# ESP32S31_RADIO register map
Vendor: Espressif; Series: ESP32-S31; File version: 3.52
Registers are 32-bit, read-write, no defined reset value unless marked. A register's access mark holds for its fields unless they carry their own. Offsets are from the block's base; [hi:lo] are bit positions; 'fields as' and 'values as' point back to an identical list.

## PHY_BASEBAND_CONFIG_ORACLE — PHY/baseband configuration registers recovered from complete rev0 ROM bodies and complete pinned libphy leaves. Operation-derived fields keep UNKNOWN where neither public documentation nor an independent symbol establishes the electrical meaning.
Base 0x20100000
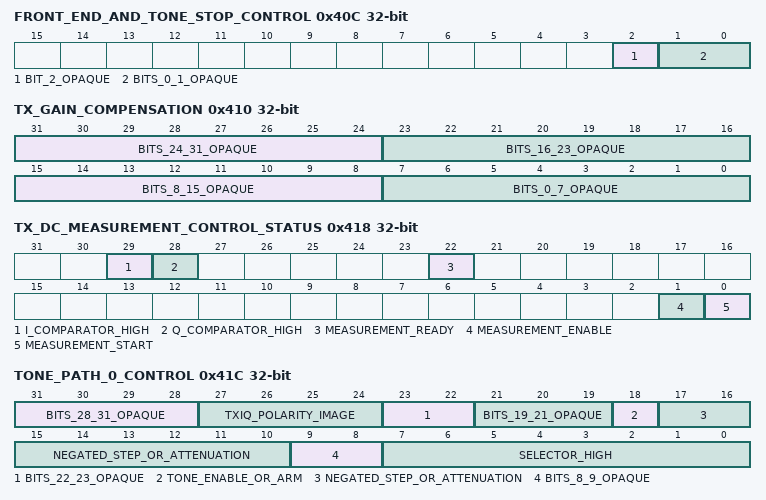
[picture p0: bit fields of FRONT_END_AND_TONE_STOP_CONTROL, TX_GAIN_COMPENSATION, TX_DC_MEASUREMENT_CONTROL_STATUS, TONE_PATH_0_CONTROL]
0x40C FRONT_END_AND_TONE_STOP_CONTROL — Project-assigned name. Shared word whose bit 2 is set by complete phy_fe_reg_init. Complete phy_start_tx_tone_step clears bits 1:0 and complete phy_stop_tx_tone sets them.
  [2] BIT_2_OPAQUE — Opaque: meaning not established.
  [1:0] BITS_0_1_OPAQUE — Opaque: meaning not established. Two-bit field cleared before the ROM power-control tone and set by its complete cleanup; the individual bit meanings are unknown.
0x410 TX_GAIN_COMPENSATION — Project-assigned name. Complete phy_txgain_comp_pacfg_new(1) publishes four ordered byte updates.
  [31:24] BITS_24_31_OPAQUE — Opaque: meaning not established.
  [23:16] BITS_16_23_OPAQUE — Opaque: meaning not established.
  [15:8] BITS_8_15_OPAQUE — Opaque: meaning not established.
  [7:0] BITS_0_7_OPAQUE — Opaque: meaning not established.
0x414 TX_GAIN_COMPENSATION_AUX wo — Project-assigned name. Pinned libphy.a[phy_reg.o] phy_start_tx_tone_step_new writes the full zero image while disabling TX-gain compensation.
  [31:0] BITS_0_31_OPAQUE — Opaque: meaning not established.
0x418 TX_DC_MEASUREMENT_CONTROL_STATUS — Project-assigned name. Complete phy_txdc_cal triggers measurement with bits 1 and 0, polls ready bit 22, samples I and Q comparator bits 29 and 28 through independent reads, then clears bits 1 and 0.
  [29] I_COMPARATOR_HIGH ro — Project-assigned name.
  [28] Q_COMPARATOR_HIGH ro — Project-assigned name.
  [22] MEASUREMENT_READY ro — Project-assigned name.
  [1] MEASUREMENT_ENABLE — Project-assigned name.
  [0] MEASUREMENT_START — Project-assigned name.
0x41C TONE_PATH_0_CONTROL — Project-assigned name. First calibration-tone path word. Complete source bodies prove the packed selector, negated step or attenuation, enable/arm bit and TX-IQ mismatch images; the high nibble is preserved and remains electrically unknown.
  [31:28] BITS_28_31_OPAQUE — Opaque: meaning not established. High nibble preserved by all recovered tone updates and retained by the TX-IQ save/restore transaction.
  [27:24] TXIQ_POLARITY_IMAGE — Project-assigned name. Four-bit mismatch polarity image: first configuration writes bit 26, while the second phase writes nibble 1 or 8.
  [23:22] BITS_22_23_OPAQUE — Opaque: meaning not established. Complete general and first-polarity tone writers clear these bits.
  [21:19] BITS_19_21_OPAQUE — Opaque: meaning not established. Three-bit image set to binary 101 for the first mismatch-power polarity and otherwise cleared by general tone setup.
  [18] TONE_ENABLE_OR_ARM — Project-assigned name. Set by tone start and by each PWDET sample-arm edge; cleared by stop and sample cleanup.
  [17:10] NEGATED_STEP_OR_ATTENUATION — Project-assigned name. Two's-complement negated eight-bit tone step or attenuation.
  [9:8] BITS_8_9_OPAQUE — Opaque: meaning not established. Complete tone writers clear these bits; their hardware meaning is unknown.
  [7:0] SELECTOR_HIGH — Project-assigned name. Upper eight bits of the evidenced ten-bit selector; bits 1:0 are in TONE_SELECTOR_CONTROL.
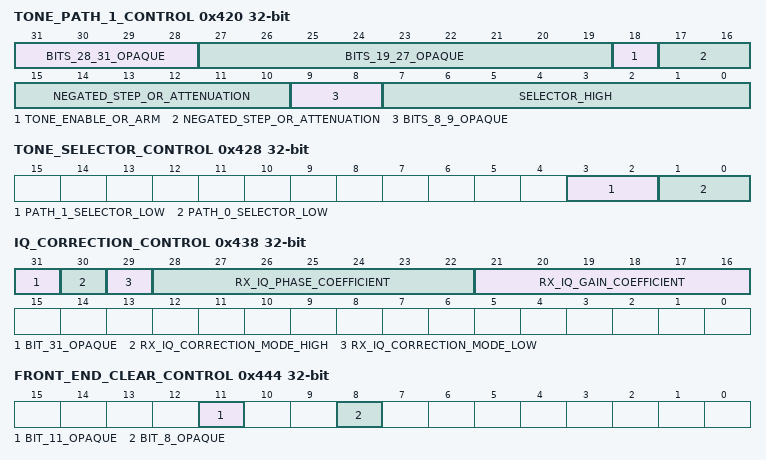
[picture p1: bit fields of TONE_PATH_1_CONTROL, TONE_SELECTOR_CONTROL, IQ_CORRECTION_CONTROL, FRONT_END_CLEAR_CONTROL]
0x420 TONE_PATH_1_CONTROL — Project-assigned name. Second calibration-tone path word. All currently evidenced calls publish a disabled zero low image while preserving the high nibble.
  [31:28] BITS_28_31_OPAQUE — Opaque: meaning not established. High nibble preserved by all recovered second-path tone updates.
  [27:19] BITS_19_27_OPAQUE — Opaque: meaning not established.
    0=CLEARED
  [18] TONE_ENABLE_OR_ARM — Project-assigned name.
  [17:10] NEGATED_STEP_OR_ATTENUATION — Project-assigned name.
    0=CLEARED
  [9:8] BITS_8_9_OPAQUE — Opaque: meaning not established.
    0=CLEARED
  [7:0] SELECTOR_HIGH — Project-assigned name.
    0=CLEARED
0x424 RX_GAIN_DC_CONTROL — Project-assigned name. Complete rev0 ROM phy_set_rx_gain_cal_dc at 0x2f829858, size 0x206, sets bits 6:5 before the bounded RX-gain DC calibration graph and clears the same pair during the common cleanup tail. Their narrower electrical meaning is not independently proved.
  [6:5] BITS_5_6_OPAQUE — Opaque: meaning not established.
    0=DISABLED (Common phy_set_rx_gain_cal_dc cleanup value.); 3=ENABLED (phy_set_rx_gain_cal_dc calibration-prefix value.)
0x428 TONE_SELECTOR_CONTROL — Project-assigned name. Low two selector bits for each calibration-tone path, updated through separate fresh-read edges.
  [3:2] PATH_1_SELECTOR_LOW — Project-assigned name.
  [1:0] PATH_0_SELECTOR_LOW — Project-assigned name.
0x438 IQ_CORRECTION_CONTROL — Project-assigned name. Shared RX-IQ coefficient and correction-mode word.
  [31] BIT_31_OPAQUE — Opaque: meaning not established. Complete phy_fe_reg_init sets bit 31 after the repeated ADC-control writes.
  [30] RX_IQ_CORRECTION_MODE_HIGH — Project-assigned name. High bit of the correction-mode field updated through a distinct fresh-read edge by the RXIQ parent.
  [29] RX_IQ_CORRECTION_MODE_LOW — Project-assigned name. Low bit of the correction-mode field updated through a distinct fresh-read edge by the RXIQ parent.
  [28:22] RX_IQ_PHASE_COEFFICIENT — Project-assigned name.
  [21:16] RX_IQ_GAIN_COEFFICIENT — Project-assigned name.
0x444 FRONT_END_CLEAR_CONTROL — Project-assigned name. Complete phy_fe_reg_init clears bits 8 and 11 in two separately ordered RMW edges.
  [11] BIT_11_OPAQUE — Opaque: meaning not established.
  [8] BIT_8_OPAQUE — Opaque: meaning not established.
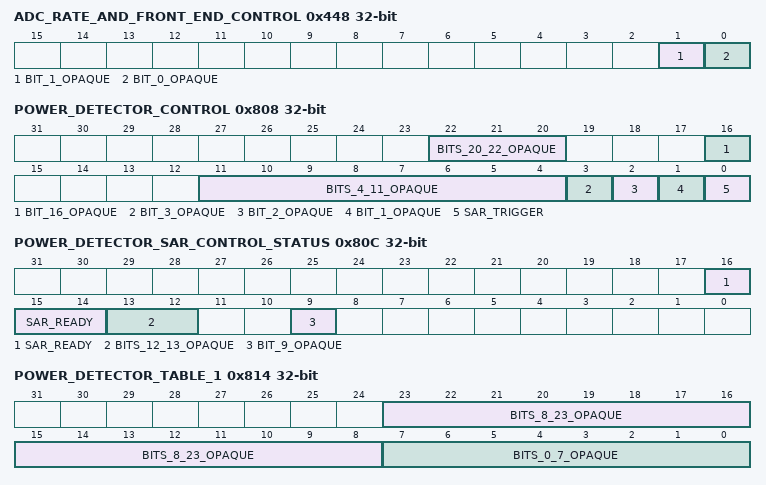
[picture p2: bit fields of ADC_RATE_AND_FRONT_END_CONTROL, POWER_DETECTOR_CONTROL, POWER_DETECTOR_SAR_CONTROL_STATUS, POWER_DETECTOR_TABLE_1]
0x448 ADC_RATE_AND_FRONT_END_CONTROL — Project-assigned name. Complete phy_adc_rate_set and phy_dac_rate_set publish rate bit zero into bits 1 and 0 through separate RMW edges. Front-end initialization and update set the same bits in their independently evidenced order.
  [1] BIT_1_OPAQUE — Opaque: meaning not established.
  [0] BIT_0_OPAQUE — Opaque: meaning not established.
0x808 POWER_DETECTOR_CONTROL — Project-assigned name. Shared PWDET trigger, calibration and background-control word.
  [22:20] BITS_20_22_OPAQUE — Opaque: meaning not established.
  [16] BIT_16_OPAQUE — Opaque: meaning not established.
  [11:4] BITS_4_11_OPAQUE — Opaque: meaning not established.
  [3] BIT_3_OPAQUE — Opaque: meaning not established.
  [2] BIT_2_OPAQUE — Opaque: meaning not established.
  [1] BIT_1_OPAQUE — Opaque: meaning not established.
  [0] SAR_TRIGGER — Project-assigned name.
0x80C POWER_DETECTOR_SAR_CONTROL_STATUS — Project-assigned name. PWDET SAR configuration and three-bit ready status.
  [16:14] SAR_READY ro — Project-assigned name. Hardware completion state sampled by the complete power-detector paths; neither source writes these bits.
  [13:12] BITS_12_13_OPAQUE — Opaque: meaning not established.
  [9] BIT_9_OPAQUE — Opaque: meaning not established.
0x810 WORD_0810_OPAQUE wo — Opaque: meaning not established. Complete phy_pwdet_reg_init writes 0x0f0f0fff.
0x814 POWER_DETECTOR_TABLE_1 — Project-assigned name. Complete initialization writes 0x00ff0f64; TX-DC calibration temporarily replaces the low byte.
  [23:8] BITS_8_23_OPAQUE — Opaque: meaning not established.
  [7:0] BITS_0_7_OPAQUE — Opaque: meaning not established.
0x818 POWER_DETECTOR_REFERENCE wo — Project-assigned name. PWDET reference word; initialization writes 0xaaaa and later paths publish 0, 0x5555 or 0xaaaa.
  [15:0] REFERENCE_CODE — Project-assigned name.
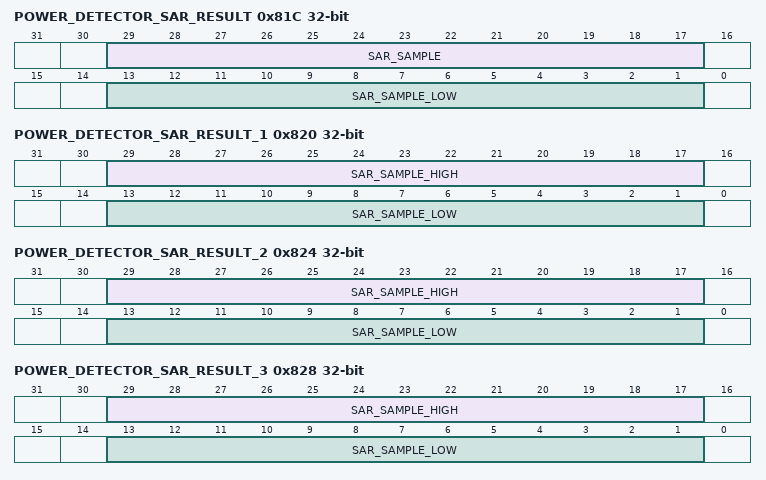
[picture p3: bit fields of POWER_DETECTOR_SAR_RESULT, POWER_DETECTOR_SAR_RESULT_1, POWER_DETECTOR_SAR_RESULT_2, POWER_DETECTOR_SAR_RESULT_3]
0x81C POWER_DETECTOR_SAR_RESULT ro — Project-assigned name. First of four consecutive SAR result words. phy_get_tone_sar_dout_ consumes its upper thirteen-bit sample; phy_get_fm_sar_dout consumes both thirteen-bit halves from all four words.
  [29:17] SAR_SAMPLE — Project-assigned name.
  [13:1] SAR_SAMPLE_LOW — Project-assigned name.
0x820 POWER_DETECTOR_SAR_RESULT_1 ro — Project-assigned name. Second of four consecutive dual thirteen-bit SAR result words consumed by complete phy_get_fm_sar_dout.
  [29:17] SAR_SAMPLE_HIGH — Project-assigned name.
  [13:1] SAR_SAMPLE_LOW — Project-assigned name.
0x824 POWER_DETECTOR_SAR_RESULT_2 ro — Project-assigned name. Third of four consecutive dual thirteen-bit SAR result words consumed by complete phy_get_fm_sar_dout.
  fields as POWER_DETECTOR_SAR_RESULT_1
0x828 POWER_DETECTOR_SAR_RESULT_3 ro — Project-assigned name. Fourth of four consecutive dual thirteen-bit SAR result words consumed by complete phy_get_fm_sar_dout.
  fields as POWER_DETECTOR_SAR_RESULT_1
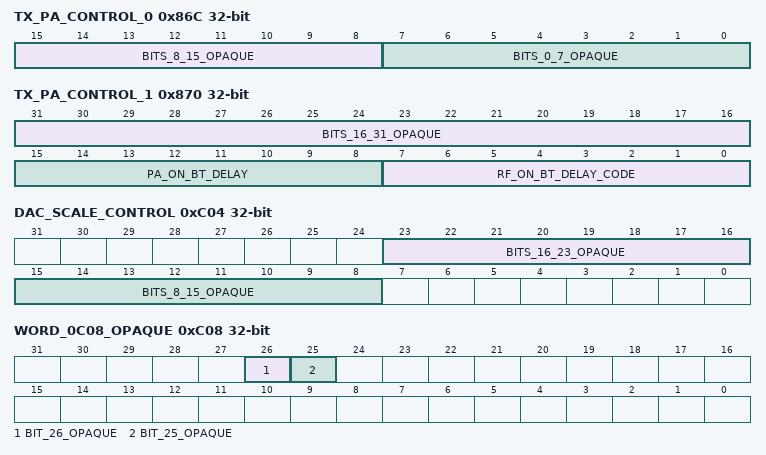
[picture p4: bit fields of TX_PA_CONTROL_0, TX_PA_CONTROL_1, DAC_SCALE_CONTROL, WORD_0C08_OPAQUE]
0x86C TX_PA_CONTROL_0 — Project-assigned name. Shared front-end low byte and PA-on high byte.
  [15:8] BITS_8_15_OPAQUE — Opaque: meaning not established.
  [7:0] BITS_0_7_OPAQUE — Opaque: meaning not established.
0x870 TX_PA_CONTROL_1 — Project-assigned name. Complete phy_tx_paon_set publishes 0x0a0e in the high half and 0xc8 in byte one. Complete ble_tx_config_check independently names the low two bytes as Bluetooth RF/PA turn-on delays.
  [31:16] BITS_16_31_OPAQUE — Opaque: meaning not established.
  [15:8] PA_ON_BT_DELAY — Project-assigned name. Bluetooth PA-on delay.
  [7:0] RF_ON_BT_DELAY_CODE — Project-assigned name. Eight-bit RF-on delay code printed by the vendor checker after integer division by 80. The electrical time unit of the raw code is not otherwise assumed.
0xC04 DAC_SCALE_CONTROL — Project-assigned name. Complete ROM tone start clears both byte-wide DAC-scale fields before measurement; complete phy_stop_tx_tone(1) restores both fields to 0xff through separate fresh-read writes.
  [23:16] BITS_16_23_OPAQUE — Opaque: meaning not established.
  [15:8] BITS_8_15_OPAQUE — Opaque: meaning not established.
0xC08 WORD_0C08_OPAQUE — Opaque: meaning not established. Both complete source bodies set bit 25 and then bit 26 through separate fresh-read RMW edges.
  [26] BIT_26_OPAQUE — Opaque: meaning not established.
  [25] BIT_25_OPAQUE — Opaque: meaning not established.
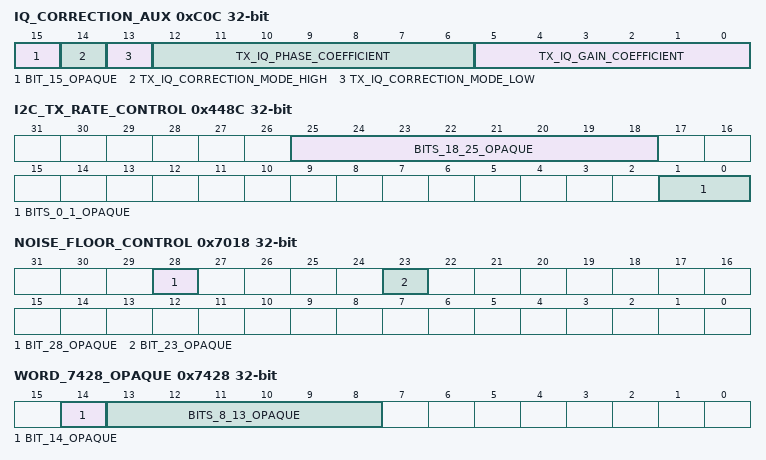
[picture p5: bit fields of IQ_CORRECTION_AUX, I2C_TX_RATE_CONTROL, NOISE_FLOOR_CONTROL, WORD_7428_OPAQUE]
0xC0C IQ_CORRECTION_AUX — Project-assigned name. Shared TX-IQ coefficient and correction-mode word.
  [15] BIT_15_OPAQUE — Opaque: meaning not established. Complete phy_fe_reg_init sets bit 15 after the shared correction-mode initialization.
  [14] TX_IQ_CORRECTION_MODE_HIGH — Project-assigned name. High bit of the auxiliary correction-mode field updated through a distinct fresh-read edge by the RXIQ parent.
  [13] TX_IQ_CORRECTION_MODE_LOW — Project-assigned name. Low bit of the auxiliary correction-mode field updated through a distinct fresh-read edge by the RXIQ parent.
  [12:6] TX_IQ_PHASE_COEFFICIENT — Project-assigned name.
  [5:0] TX_IQ_GAIN_COEFFICIENT — Project-assigned name.
0xC20 WORD_0C20_OPAQUE — Opaque: meaning not established. Final complete phy_fe_reg_init RMW replaces the low byte with 0x57.
  [7:0] BITS_0_7_OPAQUE — Opaque: meaning not established.
0x448C I2C_TX_RATE_CONTROL — Project-assigned name. Complete phy_i2c_txrate_init replaces both evidenced rate fields before dispatching TX-gain compensation.
  [25:18] BITS_18_25_OPAQUE — Opaque: meaning not established.
  [1:0] BITS_0_1_OPAQUE — Opaque: meaning not established.
0x7018 NOISE_FLOOR_CONTROL — Project-assigned name. Complete phy_noise_floor_auto_set sets both control bits.
  [28] BIT_28_OPAQUE — Opaque: meaning not established.
  [23] BIT_23_OPAQUE — Opaque: meaning not established.
0x7400 WORD_7400_OPAQUE — Opaque: meaning not established. Complete phy_bb_reg_init sets bits 14:13.
  [14:13] BITS_13_14_OPAQUE — Opaque: meaning not established.
0x7428 WORD_7428_OPAQUE — Opaque: meaning not established. Complete phy_bb_reg_init sets bit 14 and replaces bits 13:8 with 0x15.
  [14] BIT_14_OPAQUE — Opaque: meaning not established.
  [13:8] BITS_8_13_OPAQUE — Opaque: meaning not established.
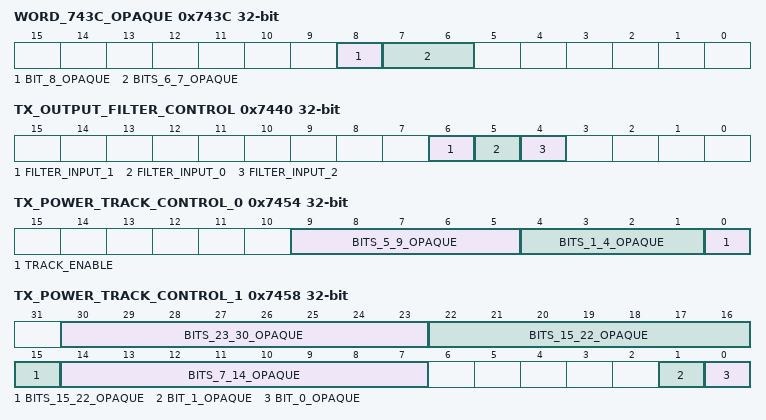
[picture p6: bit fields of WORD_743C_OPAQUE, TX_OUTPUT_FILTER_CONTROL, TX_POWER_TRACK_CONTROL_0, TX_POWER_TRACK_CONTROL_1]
0x743C WORD_743C_OPAQUE — Opaque: meaning not established. Complete phy_bb_reg_init clears bits 8:6 through two fresh-read updates.
  [8] BIT_8_OPAQUE — Opaque: meaning not established.
  [7:6] BITS_6_7_OPAQUE — Opaque: meaning not established.
0x7440 TX_OUTPUT_FILTER_CONTROL — Project-assigned name. Complete phy_bbtx_outfilter replaces bits five, six and four through three independent fresh-read RMWs.
  [6] FILTER_INPUT_1 — Project-assigned name.
  [5] FILTER_INPUT_0 — Project-assigned name.
  [4] FILTER_INPUT_2 — Project-assigned name.
0x7454 TX_POWER_TRACK_CONTROL_0 — Project-assigned name. Complete phy_bb_txpwr_track publishes enable plus two initialization fields.
  [9:5] BITS_5_9_OPAQUE — Opaque: meaning not established.
  [4:1] BITS_1_4_OPAQUE — Opaque: meaning not established.
  [0] TRACK_ENABLE — Project-assigned name.
0x7458 TX_POWER_TRACK_CONTROL_1 — Project-assigned name. Complete phy_bb_txpwr_track clears bits 1:0 and publishes three eight-bit tracking values.
  [30:23] BITS_23_30_OPAQUE — Opaque: meaning not established.
  [22:15] BITS_15_22_OPAQUE — Opaque: meaning not established.
  [14:7] BITS_7_14_OPAQUE — Opaque: meaning not established.
  [1] BIT_1_OPAQUE — Opaque: meaning not established.
  [0] BIT_0_OPAQUE — Opaque: meaning not established.
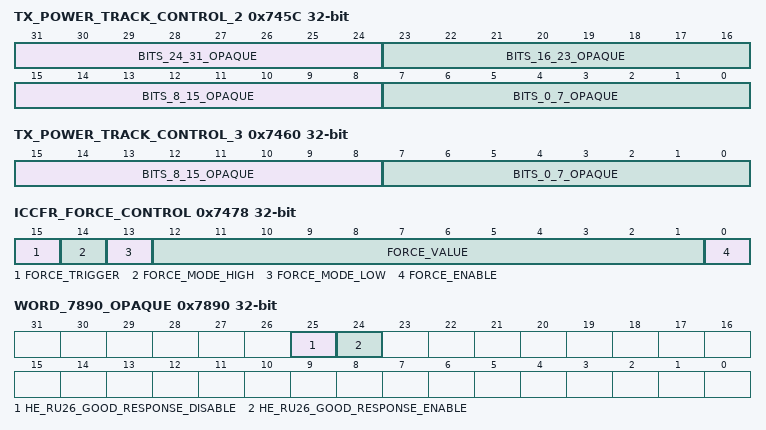
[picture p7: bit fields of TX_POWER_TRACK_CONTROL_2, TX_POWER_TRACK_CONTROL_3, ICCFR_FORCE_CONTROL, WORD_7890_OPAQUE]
0x745C TX_POWER_TRACK_CONTROL_2 — Project-assigned name. Complete phy_bb_txpwr_track publishes four byte-wide tracking values.
  fields as TX_GAIN_COMPENSATION
0x7460 TX_POWER_TRACK_CONTROL_3 — Project-assigned name. Complete phy_bb_txpwr_track publishes two byte-wide tracking values.
  fields as TX_PA_CONTROL_0
0x7468 HCCFR_CONTROL — Project-assigned name. Complete phy_config_hccfr replaces bit 22 with the low bit of its first argument.
  [22] ENABLE — Project-assigned name. Complete phy_config_hccfr writes zero to disable HCCFR and one to enable it.
    0=DISABLED (Disable HCCFR processing.); 1=ENABLED (Enable HCCFR processing.)
0x746C HCCFR_VALUE — Project-assigned name. Complete phy_config_hccfr replaces the low twelve bits with its second argument.
  [11:0] VALUE — Project-assigned name. Complete phy_config_hccfr retains the caller value to this twelve-bit field; every representable field image is accepted by the recovered leaf.
0x7478 ICCFR_FORCE_CONTROL — Project-assigned name. Complete phy_force_iccfr publishes five fields through five separately ordered fresh-read RMWs.
  [15] FORCE_TRIGGER — Project-assigned name.
  [14] FORCE_MODE_HIGH — Project-assigned name.
  [13] FORCE_MODE_LOW — Project-assigned name.
  [12:1] FORCE_VALUE — Project-assigned name. Complete phy_force_iccfr retains the caller value to this twelve-bit field; every representable field image is accepted by the recovered leaf.
  [0] FORCE_ENABLE — Project-assigned name. Complete phy_force_iccfr writes zero to disable the forced ICCFR value and one to enable it.
    0=DISABLED (Use the ordinary ICCFR value path.); 1=ENABLED (Use the forced ICCFR value.)
0x747C ICCFR_ENABLE_CONTROL — Project-assigned name. Complete phy_iccfr_en writes three to bits 26:25 for a zero argument and clears them for a nonzero argument.
  [26:25] GATE — Project-assigned name. Complete phy_iccfr_en writes zero for a nonzero enable input and three for a zero input; the other two encodings are not evidenced.
    0=ENABLED (Enable ICCFR through the recovered zero gate image.); 3=DISABLED (Disable ICCFR through the recovered all-ones gate image.)
0x7808 WORD_7808_OPAQUE — Opaque: meaning not established. Complete phy_bb_reg_init replaces bits 13:7 with 0x60.
  [13:7] BITS_7_13_OPAQUE — Opaque: meaning not established.
0x7890 WORD_7890_OPAQUE — Opaque: meaning not established. Complete phy_bb_reg_init and phy_hemu_ru26_good_res both clear bit 25 then set bit 24 through separate fresh-read RMWs.
  [25] HE_RU26_GOOD_RESPONSE_DISABLE — Project-assigned name.
  [24] HE_RU26_GOOD_RESPONSE_ENABLE — Project-assigned name.
0x78DC WORD_78DC_OPAQUE — Opaque: meaning not established. Complete phy_bb_reg_init replaces bits 13:7 with two.
  [13:7] BITS_7_13_OPAQUE — Opaque: meaning not established.
0x78E4 WORD_78E4_OPAQUE — Opaque: meaning not established. Complete phy_bb_reg_init clears bit 22.
  [22] BIT_22_OPAQUE — Opaque: meaning not established.
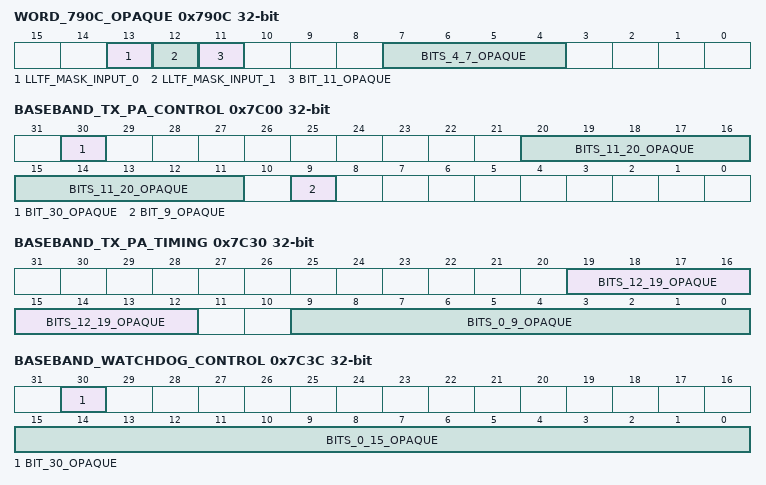
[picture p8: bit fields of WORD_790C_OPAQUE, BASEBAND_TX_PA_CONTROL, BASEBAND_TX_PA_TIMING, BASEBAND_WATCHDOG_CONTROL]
0x790C WORD_790C_OPAQUE — Opaque: meaning not established. Complete phy_bb_reg_init clears bit 11; complete phy_lltf_mask_en independently replaces bits thirteen and twelve; complete phy_chan_dump_cfg replaces bits 7:4 and bit 11 through separate fresh-read RMWs.
  [13] LLTF_MASK_INPUT_0 — Project-assigned name.
  [12] LLTF_MASK_INPUT_1 — Project-assigned name.
  [11] BIT_11_OPAQUE — Opaque: meaning not established.
  [7:4] BITS_4_7_OPAQUE — Opaque: meaning not established. Complete phy_chan_dump_cfg replaces bits 7:4 with the low nibble of its first argument.
0x7980 WORD_7980_OPAQUE — Opaque: meaning not established. Complete phy_bb_reg_init clears bit 25.
  [25] BIT_25_OPAQUE — Opaque: meaning not established.
0x7A28 WORD_7A28_OPAQUE — Opaque: meaning not established. Complete phy_bb_reg_init clears bit 22.
  [22] BIT_22_OPAQUE — Opaque: meaning not established.
0x7C00 BASEBAND_TX_PA_CONTROL — Project-assigned name. Complete phy_bb_reg_init sets bit 9; complete phy_tx_paon_set replaces bits 20:11; complete phy_chan_dump_cfg replaces bit 30 with the low bit of its second argument.
  [30] BIT_30_OPAQUE — Opaque: meaning not established. Complete phy_chan_dump_cfg replaces bit 30 with the low bit of its second argument.
  [20:11] BITS_11_20_OPAQUE — Opaque: meaning not established.
  [9] BIT_9_OPAQUE — Opaque: meaning not established.
0x7C08 BASEBAND_WATCHDOG_STATUS ro — Project-assigned name. Complete phy_bb_wdt_get_status returns one unrestricted full-word read.
  [31:0] STATUS — Project-assigned name. Complete unrestricted watchdog status value returned by phy_bb_wdt_get_status.
0x7C30 BASEBAND_TX_PA_TIMING — Project-assigned name. Complete phy_bb_reg_init clears bits 19:12; complete phy_tx_paon_set replaces bits 9:0 with 0x1e.
  [19:12] BITS_12_19_OPAQUE — Opaque: meaning not established.
  [9:0] BITS_0_9_OPAQUE — Opaque: meaning not established.
0x7C3C BASEBAND_WATCHDOG_CONTROL — Project-assigned name. Complete phy_bb_wdg_cfg publishes low configuration 0x00aa and sets bit 30.
  [30] BIT_30_OPAQUE — Opaque: meaning not established.
  [15:0] BITS_0_15_OPAQUE — Opaque: meaning not established.
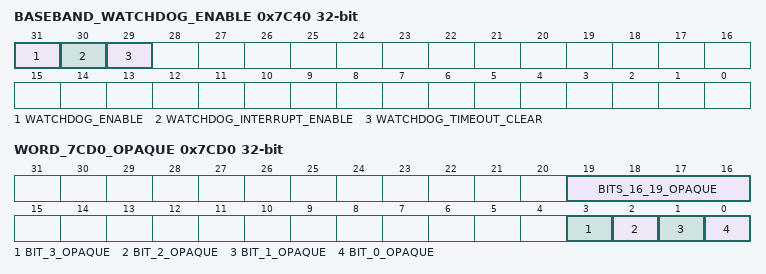
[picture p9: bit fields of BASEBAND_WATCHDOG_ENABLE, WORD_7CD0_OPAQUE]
0x7C40 BASEBAND_WATCHDOG_ENABLE — Project-assigned name. Complete phy_bb_wdg_cfg sets bit 31. The standalone watchdog leaves replace bits 31 and 30 and set timeout-clear bit 29.
  [31] WATCHDOG_ENABLE — Project-assigned name.
  [30] WATCHDOG_INTERRUPT_ENABLE — Project-assigned name.
  [29] WATCHDOG_TIMEOUT_CLEAR — Project-assigned name.
0x7C44 NOISE_FLOOR_ENABLE_0 — Project-assigned name. Complete phy_noise_floor_auto_set sets bit zero.
  [0] BIT_0_OPAQUE — Opaque: meaning not established.
0x7C50 NOISE_FLOOR_ENABLE_1 — Project-assigned name. Complete phy_noise_floor_auto_set sets bit zero.
  [0] BIT_0_OPAQUE — Opaque: meaning not established.
0x7C6C WORD_7C6C_OPAQUE wo — Opaque: meaning not established. Complete phy_tx_paon_set writes 0x0661a45f.
0x7CA8 WORD_7CA8_OPAQUE — Opaque: meaning not established. Complete phy_bb_reg_init sets bit 20.
  [20] BIT_20_OPAQUE — Opaque: meaning not established.
0x7CD0 WORD_7CD0_OPAQUE — Opaque: meaning not established. Complete phy_bb_reg_init sets both nibbles to 0xf; complete phy_btbb_wifi_bb_cfg2 preserves low bit two, sets the other low bits and sets the high nibble.
  [19:16] BITS_16_19_OPAQUE — Opaque: meaning not established.
  [3] BIT_3_OPAQUE — Opaque: meaning not established.
  [2] BIT_2_OPAQUE — Opaque: meaning not established. Complete phy_btbb_wifi_bb_cfg2 preserves this bit while setting the other low-nibble bits.
  [1] BIT_1_OPAQUE — Opaque: meaning not established.
  [0] BIT_0_OPAQUE — Opaque: meaning not established.
